# ATxmega128A1 register map
Vendor: Atmel; File version: 1.0
CPU: other r0p0, little endian, no MPU, no FPU, 4 interrupt priority bits
Registers are 8-bit, read-write, reset 0x0 unless marked. A register's access mark holds for its fields unless they carry their own. Offsets are from the block's base; [hi:lo] are bit positions; {n}, {i} and the like mark numbered series; 'fields as' and 'values as' point back to an identical list.

## OCD — On-Chip Debug System
Base 0x0000002E
0x00 OCDR0 — OCD Register 0
  [7:0] OCDRD — OCDR Dirty
0x01 OCDR1 — OCD Register 1
  [0] OCDRD — OCDR Dirty

## OSC — Oscillator
Base 0x00000050
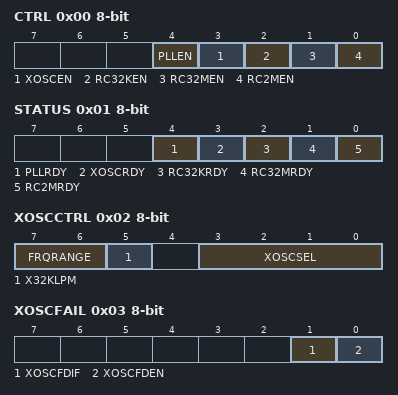
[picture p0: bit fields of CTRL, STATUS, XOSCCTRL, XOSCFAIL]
0x00 CTRL — Control Register
  [4] PLLEN — PLL Enable
  [3] XOSCEN — External Oscillator Enable
  [2] RC32KEN — Internal 32kHz RC Oscillator Enable
  [1] RC32MEN — Internal 32MHz RC Oscillator Enable
  [0] RC2MEN — Internal 2MHz RC Oscillator Enable
0x01 STATUS
  [4] PLLRDY — PLL Ready
  [3] XOSCRDY — External Oscillator Ready
  [2] RC32KRDY — Internal 32kHz RC Oscillator Ready
  [1] RC32MRDY — Internal 32MHz RC Oscillator Ready
  [0] RC2MRDY — Internal 2MHz RC Oscillator Ready
0x02 XOSCCTRL — External Oscillator Control Register
  [7:6] FRQRANGE — Frequency Range
    0=04TO2 (0.4 - 2 MHz); 1=2TO9 (2 - 9 MHz); 2=9TO12 (9 - 12 MHz); 3=12TO16 (12 - 16 MHz)
  [5] X32KLPM — 32kHz XTAL OSC Low-power Mode
  [3:0] XOSCSEL — External Oscillator Selection and Startup Time
    0=EXTCLK (External Clock - 6 CLK); 2=32kHz TOSC - 32K CLK; 3=XTAL_256CLK (0.4-16MHz XTAL - 256 CLK); 7=XTAL_1KCLK (0.4-16MHz XTAL - 1K CLK); 11=XTAL_16KCLK (0.4-16MHz XTAL - 16K CLK)
0x03 XOSCFAIL — External Oscillator Failure Detection Register
  [1] XOSCFDIF — Failure Detection Interrupt Flag
  [0] XOSCFDEN — Failure Detection Enable
0x04 RC32KCAL — 32kHz Internal Oscillator Calibration Register
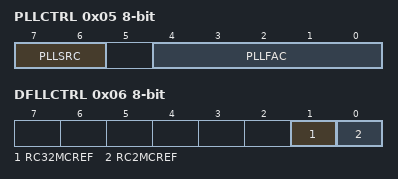
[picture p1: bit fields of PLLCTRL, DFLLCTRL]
0x05 PLLCTRL — PLL Control REgister
  [7:6] PLLSRC — Clock Source
    0=RC2M (Internal 2MHz RC Oscillator); 2=RC32M (Internal 32MHz RC Oscillator); 3=XOSC (External Oscillator)
  [4:0] PLLFAC — Multiplication Factor
0x06 DFLLCTRL — DFLL Control Register
  [1] RC32MCREF — 32MHz Calibration Reference
  [0] RC2MCREF — 2MHz Calibration Reference

## PMIC — Programmable Multi-level Interrupt Controller
Base 0x000000A0
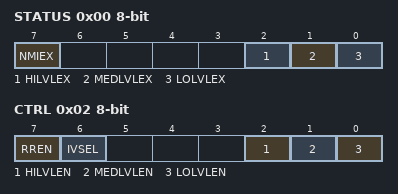
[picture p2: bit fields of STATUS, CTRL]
0x00 STATUS
  [7] NMIEX — Non-maskable Interrupt Executing
  [2] HILVLEX — High Level Interrupt Executing
  [1] MEDLVLEX — Medium Level Interrupt Executing
  [0] LOLVLEX — Low Level Interrupt Executing
0x01 INTPRI — Interrupt Priority
0x02 CTRL — Control Register
  [7] RREN — Round-Robin Priority Enable
  [6] IVSEL — Interrupt Vector Select
  [2] HILVLEN — High Level Enable
  [1] MEDLVLEN — Medium Level Enable
  [0] LOLVLEN — Low Level Enable

## PORTA — Port Configuration
Base 0x00000600
Same registers: PORTB 0x00000620, PORTC 0x00000640, PORTD 0x00000660, PORTE 0x00000680, PORTF 0x000006A0, PORTH 0x000006E0, PORTJ 0x00000700, PORTK 0x00000720, PORTQ 0x000007C0, PORTR 0x000007E0
0x00 DIR — I/O Port Data Direction
0x01 DIRSET — I/O Port Data Direction Set
0x02 DIRCLR — I/O Port Data Direction Clear
0x03 DIRTGL — I/O Port Data Direction Toggle
0x04 OUT — I/O Port Output
0x05 OUTSET — I/O Port Output Set
0x06 OUTCLR — I/O Port Output Clear
0x07 OUTTGL — I/O Port Output Toggle
0x08 IN — I/O port Input
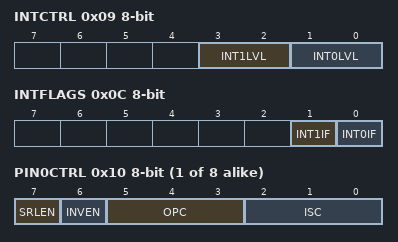
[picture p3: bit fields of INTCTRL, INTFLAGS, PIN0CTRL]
0x09 INTCTRL — Interrupt Control Register
  [3:2] INT1LVL — Port Interrupt 1 Level
    0=OFF (Interrupt Disabled); 1=LO (Low Level); 2=MED (Medium Level); 3=HI (High Level)
  [1:0] INT0LVL — Port Interrupt 0 Level
    values as INT1LVL
0x0A INT0MASK — Port Interrupt 0 Mask
0x0B INT1MASK — Port Interrupt 1 Mask
0x0C INTFLAGS — Interrupt Flag Register
  [1] INT1IF — Port Interrupt 1 Flag
  [0] INT0IF — Port Interrupt 0 Flag
{0x10+i} PIN{i}CTRL (i=0..7) — Pin {i} Control Register
  [7] SRLEN — Slew Rate Enable
  [6] INVEN — Inverted I/O Enable
  [5:3] OPC — Output/Pull Configuration
    0=TOTEM (Totempole); 1=BUSKEEPER (Totempole w/ Bus keeper on Input and Output); 2=PULLDOWN (Totempole w/ Pull-down on Input); 3=PULLUP (Totempole w/ Pull-up on Input); 4=WIREDOR; 5=WIREDAND; 6=WIREDORPULL (Wired OR w/ Pull-down); 7=WIREDANDPULL (Wired AND w/ Pull-up)
  [2:0] ISC — Input/Sense Configuration
    0=BOTHEDGES (Sense Both Edges); 1=RISING (Sense Rising Edge); 2=FALLING (Sense Falling Edge); 3=LEVEL (Sense Level (Transparent For Events)); 7=INPUT_DISABLE (Disable Digital Input Buffer)
